VERSION ""

NS_ :

BS_:

BU_: DVT_Cntrl VehDynCntrl
VAL_TABLE_ SpeedLimit_Source 7 "Reverse Limit" 6 "DTS Fault Limit" 5 "Limp Mode Limit" 4 "ADAS Limit" 3 "HMI Limit" 2 "Safety Limit" 1 "Critical Motor Speed Limit" 0 "No Limit" ;
VAL_TABLE_ MapCheckStatus 2 "Parameters incorrect" 1 "Parameters selectively correct" 0 "Parameters correct" ;
VAL_TABLE_ DrRA_BrPedState 3 "Error" 2 "is being pressed" 1 "is not being pressed" 0 "Not avaible" ;
VAL_TABLE_ DVT_DrRA_Prms_Chk_St 2 "DrRA_P_SCor" 1 "DrRA_P_Cor" 0 "DrRA_P_Incor" ;
VAL_TABLE_ DVT_Chosen_Ctrl 1 "Ctrl_fr_AccP" 0 "Ctrl_fr_AI" ;

BO_ 3221225472 VECTOR__INDEPENDENT_SIG_MSG: 0 Vector__XXX
 SG_ ORTL_OTLIM : 0|4@1+ (500,0) [0|7500] "Nm" Vector__XXX
 SG_ ORTL_ORLIM : 0|4@1+ (500,0) [0|7500] "Nm" Vector__XXX
 SG_ ELPC_OvrldCoef : 0|8@1+ (1,0) [0|255] "%" Vector__XXX
 SG_ TrqLimBySpeed : 0|1@1+ (1,0) [0|1] "" Vector__XXX
 SG_ DrRA_P_ChkSt : 0|2@1+ (1,0) [0|0] "" Vector__XXX
 SG_ RotCritMot2Spd : 0|8@1+ (130,0) [0|33150] "RPM" Vector__XXX
 SG_ RotCritMot1Spd : 0|8@1+ (130,0) [0|33150] "RPM" Vector__XXX
 SG_ FreeDebugFlag2 : 0|1@1+ (1,0) [0|0] "" Vector__XXX
 SG_ FreeDebugFlag1 : 0|1@1+ (1,0) [0|0] "" Vector__XXX
 SG_ IsBrPedPushed : 0|1@1+ (1,0) [0|1] "" Vector__XXX
 SG_ IsBreakPedError : 0|1@1+ (1,0) [0|1] "" Vector__XXX
 SG_ PedalErrorProcessing : 0|1@1+ (1,0) [0|0] "" Vector__XXX
 SG_ IntVehSpdLim : 0|8@1+ (1,0) [0|255] "kph" Vector__XXX
 SG_ TTLimSpdLim : 0|1@1+ (1,0) [0|0] "" Vector__XXX
 SG_ SST_TrqOut : 0|16@1+ (1,-32768) [-32768|32767] "Nm" Vector__XXX
 SG_ RSPDL_DTSFault_LimitValid : 0|1@1+ (1,0) [0|1] "" Vector__XXX

BO_ 2381399806 DVT_RSPDL_Debug: 8 Vector__XXX
 SG_ LMP_LimpReqSrc7 : 55|1@1+ (1,0) [0|1] "" Vector__XXX
 SG_ LMP_LimpRequest : 57|1@1+ (1,0) [0|1] "" Vector__XXX
 SG_ RSPDL_Safety_LimitValid : 60|1@1+ (1,0) [0|1] "" Vector__XXX
 SG_ RSPDL_Reverse_LimitValid : 59|1@1+ (1,0) [0|1] "" Vector__XXX
 SG_ RSPDL_LimpMode_LimitValid : 58|1@1+ (1,0) [0|1] "" Vector__XXX
 SG_ RSPDL_Internal_LimitValid : 56|1@1+ (1,0) [0|1] "" Vector__XXX
 SG_ RSPDL_LimpReq : 46|1@1+ (1,0) [0|1] "" Vector__XXX
 SG_ RSPDL_Limp_Limit : 32|8@1+ (1,0) [0|255] "kph" Vector__XXX
 SG_ RSPDL_HMI_LimitValid : 54|1@1+ (1,0) [0|1] "" Vector__XXX
 SG_ RSPDL_ADAS_LimitValid : 53|1@1+ (1,0) [0|1] "" Vector__XXX
 SG_ LMP_LimpReqSrc6 : 52|1@1+ (1,0) [0|1] "" Vector__XXX
 SG_ LMP_LimpReqSrc5 : 51|1@1+ (1,0) [0|1] "" Vector__XXX
 SG_ LMP_LimpReqSrc4 : 50|1@1+ (1,0) [0|1] "" Vector__XXX
 SG_ LMP_LimpReqSrc3 : 49|1@1+ (1,0) [0|1] "" Vector__XXX
 SG_ LMP_LimpReqSrc2 : 48|1@1+ (1,0) [0|1] "" Vector__XXX
 SG_ LMP_LimpReqSrc1 : 47|1@1+ (1,0) [0|1] "" Vector__XXX
 SG_ RSPDL_IsTqLimdBySpdLim : 45|1@1+ (1,0) [0|1] "" Vector__XXX
 SG_ VSLC_IsIntSpdLimAcv : 44|1@1+ (1,0) [0|1] "" Vector__XXX
 SG_ RSPDL_Limit_Source : 40|4@1+ (1,0) [0|15] "" Vector__XXX
 SG_ RSPDL_Internal_Limit : 24|8@1+ (1,0) [0|255] "kph" Vector__XXX
 SG_ RSPDL_HMI_Limit : 16|8@1+ (1,0) [0|255] "kph" Vector__XXX
 SG_ RSPDL_ADAS_Limit : 8|8@1+ (1,0) [0|255] "kph" Vector__XXX
 SG_ RSPDL_Actual_Limit : 0|8@1+ (1,0) [0|255] "kph" Vector__XXX

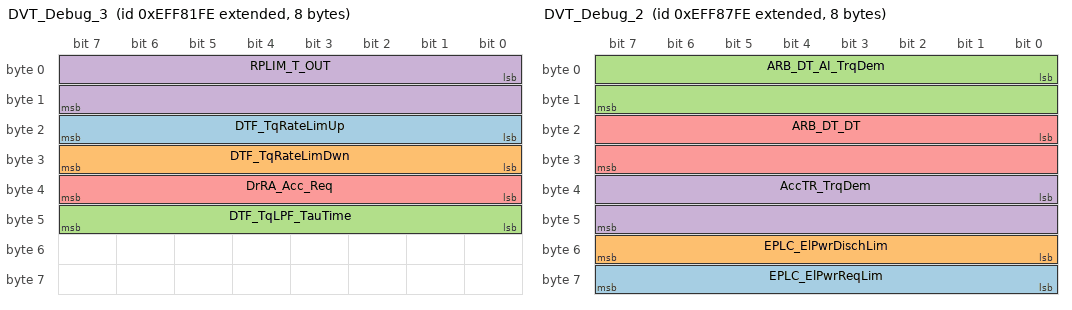
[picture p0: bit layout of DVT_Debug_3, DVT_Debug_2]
BO_ 2399109630 DVT_Debug_3: 8 Vector__XXX
 SG_ DTF_TqRateLimUp : 16|8@1+ (100,0) [0|25500] "Nm/s" Vector__XXX
 SG_ DTF_TqRateLimDwn : 24|8@1+ (100,0) [0|25500] "Nm/s" Vector__XXX
 SG_ DTF_TqLPF_TauTime : 40|8@1+ (0.01,0) [0|2.55] "sec" Vector__XXX
 SG_ RPLIM_T_OUT : 0|16@1+ (1,-32768) [-32768|32767] "Nm" Vector__XXX
 SG_ DrRA_Acc_Req : 32|8@1+ (1,-100) [-100|100] "%" Vector__XXX

BO_ 2399111166 DVT_Debug_2: 8 Vector__XXX
 SG_ EPLC_ElPwrReqLim : 56|8@1+ (10,0) [0|2550] "kW" Vector__XXX
 SG_ EPLC_ElPwrDischLim : 48|8@1+ (10,0) [0|2550] "kW" Vector__XXX
 SG_ ARB_DT_AI_TrqDem : 0|16@1- (1,0) [-32768|32767] "" Vector__XXX
 SG_ AccTR_TrqDem : 32|16@1+ (1,-32768) [-32768|32767] "N*m" Vector__XXX
 SG_ ARB_DT_DT : 16|16@1+ (1,-32768) [-32768|32767] "Nm" Vector__XXX

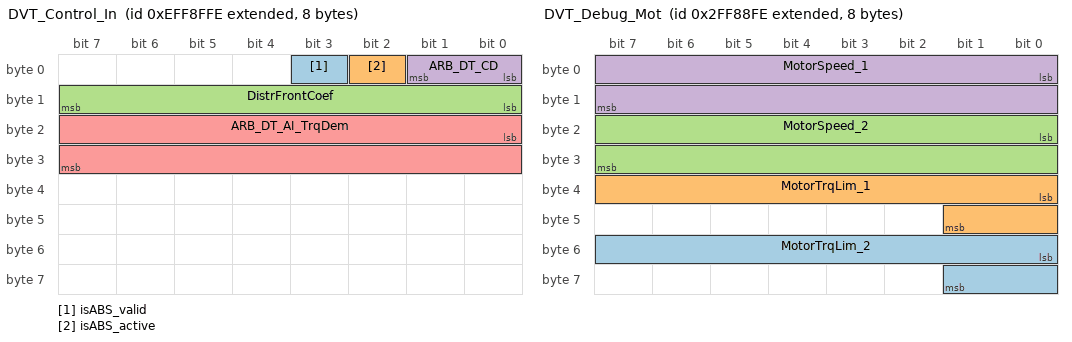
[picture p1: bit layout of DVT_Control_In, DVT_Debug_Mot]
BO_ 2399113214 DVT_Control_In: 8 Vector__XXX
 SG_ isABS_valid : 3|1@1+ (1,0) [0|1] "" Vector__XXX
 SG_ isABS_active : 2|1@1+ (1,0) [0|1] "" Vector__XXX
 SG_ DistrFrontCoef : 8|8@1+ (0.005,0) [0|1.275] "" Vector__XXX
 SG_ ARB_DT_CD : 0|2@1+ (1,0) [0|3] "" Vector__XXX
 SG_ ARB_DT_AI_TrqDem : 16|16@1- (1,0) [-32768|32767] "" Vector__XXX

BO_ 2197784830 DVT_Debug_Mot: 8 Vector__XXX
 SG_ MotorTrqLim_2 : 48|10@1+ (1,0) [0|1023] "" Vector__XXX
 SG_ MotorTrqLim_1 : 32|10@1+ (1,0) [0|1023] "" Vector__XXX
 SG_ MotorSpeed_2 : 16|16@1+ (1,0) [0|65535] "" Vector__XXX
 SG_ MotorSpeed_1 : 0|16@1+ (1,0) [0|65535] "" Vector__XXX

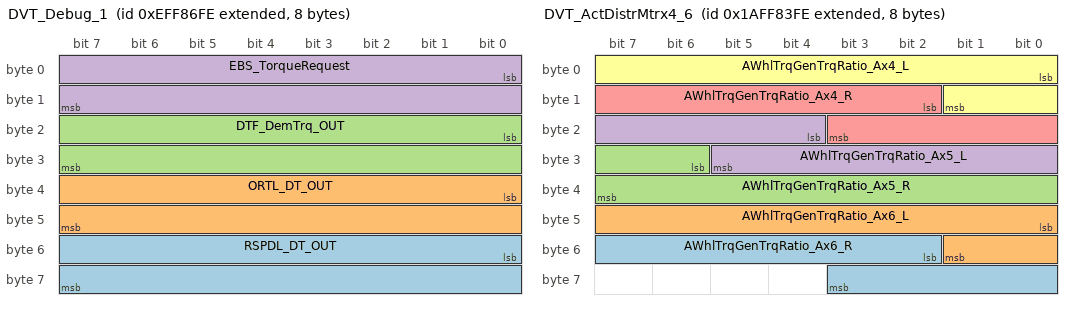
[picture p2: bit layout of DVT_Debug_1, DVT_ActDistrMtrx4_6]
BO_ 2399110910 DVT_Debug_1: 8 Vector__XXX
 SG_ RSPDL_DT_OUT : 48|16@1+ (1,-32768) [-32768|32767] "Nm" Vector__XXX
 SG_ ORTL_DT_OUT : 32|16@1+ (1,-32768) [-32768|32767] "Nm" Vector__XXX
 SG_ DTF_DemTrq_OUT : 16|16@1+ (1,-32768) [-32768|32767] "Nm" Vector__XXX
 SG_ EBS_TorqueRequest : 0|16@1+ (1,-32768) [-32768|32767] "Nm" Vector__XXX

BO_ 2600436734 DVT_ActDistrMtrx4_6: 8 DVT_Cntrl
 SG_ AWhlTrqGenTrqRatio_Ax6_R : 50|10@1+ (0.001,0) [0|1] "" Vector__XXX
 SG_ AWhlTrqGenTrqRatio_Ax6_L : 40|10@1+ (0.001,0) [0|1] "" Vector__XXX
 SG_ AWhlTrqGenTrqRatio_Ax5_R : 30|10@1+ (0.001,0) [0|1] "" Vector__XXX
 SG_ AWhlTrqGenTrqRatio_Ax5_L : 20|10@1+ (0.001,0) [0|1] "" Vector__XXX
 SG_ AWhlTrqGenTrqRatio_Ax4_R : 10|10@1+ (0.001,0) [0|1] "" Vector__XXX
 SG_ AWhlTrqGenTrqRatio_Ax4_L : 0|10@1+ (0.001,0) [0|1] "" Vector__XXX

BO_ 2600438270 DVT_Diagnostics: 8 DVT_Cntrl
 SG_ DTF_TqPreprocIsOn : 38|1@1+ (1,0) [0|0] "" Vector__XXX
 SG_ DrRA_RecChoiceProc : 32|3@1+ (1,0) [0|7] "" Vector__XXX
 SG_ DrRA_MapChoiceFwdProc : 35|3@1+ (1,0) [0|7] "" Vector__XXX
 SG_ DTF_TqLimRateIsOn : 40|1@1+ (1,0) [0|0] "" Vector__XXX
 SG_ DTF_TqLPFIsOn : 41|1@1+ (1,0) [0|0] "" Vector__XXX
 SG_ DTF_DiagWarning : 39|1@1+ (1,0) [0|0] "" Vector__XXX
 SG_ ARB_DT_TrqProhib : 25|1@1+ (1,0) [0|0] "" Vector__XXX
 SG_ ARB_DT_isTTAllow : 31|1@1+ (1,0) [0|0] "" Vector__XXX
 SG_ ARB_DT_isRTAllow : 27|1@1+ (1,0) [0|0] "" Vector__XXX
 SG_ TTDerRPLim : 26|1@1+ (1,0) [0|0] "" Vector__XXX
 SG_ TrqProactLim : 24|1@1+ (1,0) [0|0] "" Vector__XXX
 SG_ pedalProc_dbg : 28|3@1+ (1,0) [0|0] "" Vector__XXX
 SG_ ARB_DT_isABS_valid : 23|1@1+ (1,0) [0|1] "" Vector__XXX
 SG_ ARB_DT_isABS_active : 22|1@1+ (1,0) [0|1] "" Vector__XXX
 SG_ ARB_DT_CD : 20|2@1+ (1,0) [0|3] "" Vector__XXX
 SG_ DrRA_BrPedState : 18|2@1+ (1,0) [0|3] "" Vector__XXX
 SG_ ARB_CD_blocked : 17|1@1+ (1,0) [0|1] "" Vector__XXX
 SG_ ORTL_ITLimFlag : 16|1@1+ (1,0) [0|1] "" Vector__XXX
 SG_ DT_system_warn_st : 11|3@1+ (1,0) [0|7] "" Vector__XXX
 SG_ DT_GearBox_fault_st : 14|2@1+ (1,0) [0|3] "" Vector__XXX
 SG_ MapChckSt : 9|2@1+ (1,0) [0|0] "" Vector__XXX
 SG_ EBS_SrcValFlag : 8|1@1+ (1,0) [0|0] "" Vector__XXX
 SG_ IntSpdValFlag : 7|1@1+ (1,0) [0|0] "" Vector__XXX
 SG_ AccTR_Prms_Incorr : 4|1@1+ (1,0) [0|0] "" Vector__XXX
 SG_ CtrlSrcSelBlckd : 5|1@1+ (1,0) [0|0] "" Vector__XXX
 SG_ AI_SrcValFlag : 3|1@1+ (1,0) [0|0] "" Vector__XXX
 SG_ ChosenCtrlSrc : 0|2@1+ (1,0) [0|0] "" Vector__XXX
 SG_ DefDistribUnavail : 2|1@1+ (1,0) [0|0] "" Vector__XXX
 SG_ DefDistribInUse : 6|1@1+ (1,0) [0|0] "" Vector__XXX

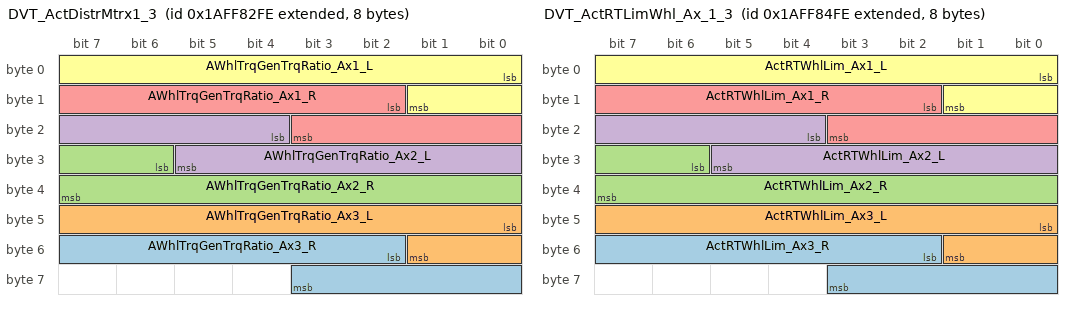
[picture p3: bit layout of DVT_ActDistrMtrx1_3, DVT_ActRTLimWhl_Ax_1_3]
BO_ 2600436478 DVT_ActDistrMtrx1_3: 8 DVT_Cntrl
 SG_ AWhlTrqGenTrqRatio_Ax3_R : 50|10@1+ (0.001,0) [0|1] "" Vector__XXX
 SG_ AWhlTrqGenTrqRatio_Ax3_L : 40|10@1+ (0.001,0) [0|1] "" Vector__XXX
 SG_ AWhlTrqGenTrqRatio_Ax2_R : 30|10@1+ (0.001,0) [0|1] "" Vector__XXX
 SG_ AWhlTrqGenTrqRatio_Ax2_L : 20|10@1+ (0.001,0) [0|1] "" Vector__XXX
 SG_ AWhlTrqGenTrqRatio_Ax1_R : 10|10@1+ (0.001,0) [0|1] "" Vector__XXX
 SG_ AWhlTrqGenTrqRatio_Ax1_L : 0|10@1+ (0.001,0) [0|1] "" Vector__XXX

BO_ 2600436990 DVT_ActRTLimWhl_Ax_1_3: 8 DVT_Cntrl
 SG_ ActRTWhlLim_Ax3_R : 50|10@1+ (8,0) [0|8144] "N*m"  VehDynCntrl
 SG_ ActRTWhlLim_Ax3_L : 40|10@1+ (8,0) [0|8144] "N*m"  VehDynCntrl
 SG_ ActRTWhlLim_Ax2_R : 30|10@1+ (8,0) [0|8144] "N*m"  VehDynCntrl
 SG_ ActRTWhlLim_Ax2_L : 20|10@1+ (8,0) [0|8144] "N*m"  VehDynCntrl
 SG_ ActRTWhlLim_Ax1_R : 10|10@1+ (8,0) [0|8144] "N*m"  VehDynCntrl
 SG_ ActRTWhlLim_Ax1_L : 0|10@1+ (8,0) [0|8144] "N*m"  VehDynCntrl

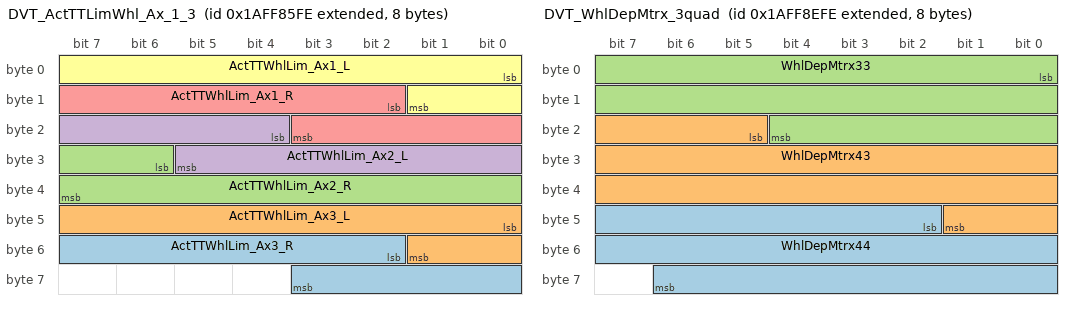
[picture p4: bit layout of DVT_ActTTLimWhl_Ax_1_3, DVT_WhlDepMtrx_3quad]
BO_ 2600437246 DVT_ActTTLimWhl_Ax_1_3: 8 DVT_Cntrl
 SG_ ActTTWhlLim_Ax3_R : 50|10@1+ (8,0) [0|8144] "N*m"  VehDynCntrl
 SG_ ActTTWhlLim_Ax3_L : 40|10@1+ (8,0) [0|8144] "N*m"  VehDynCntrl
 SG_ ActTTWhlLim_Ax2_R : 30|10@1+ (8,0) [0|8144] "N*m"  VehDynCntrl
 SG_ ActTTWhlLim_Ax2_L : 20|10@1+ (8,0) [0|8144] "N*m"  VehDynCntrl
 SG_ ActTTWhlLim_Ax1_R : 10|10@1+ (8,0) [0|8144] "N*m"  VehDynCntrl
 SG_ ActTTWhlLim_Ax1_L : 0|10@1+ (8,0) [0|8144] "N*m"  VehDynCntrl

BO_ 2600439550 DVT_WhlDepMtrx_3quad: 8 DVT_Cntrl
 SG_ WhlDepMtrx44 : 42|21@1+ (1E-005,-10) [-10|10] ""  VehDynCntrl
 SG_ WhlDepMtrx43 : 21|21@1+ (1E-005,-10) [-10|10] ""  VehDynCntrl
 SG_ WhlDepMtrx33 : 0|21@1+ (1E-005,-10) [-10|10] ""  VehDynCntrl

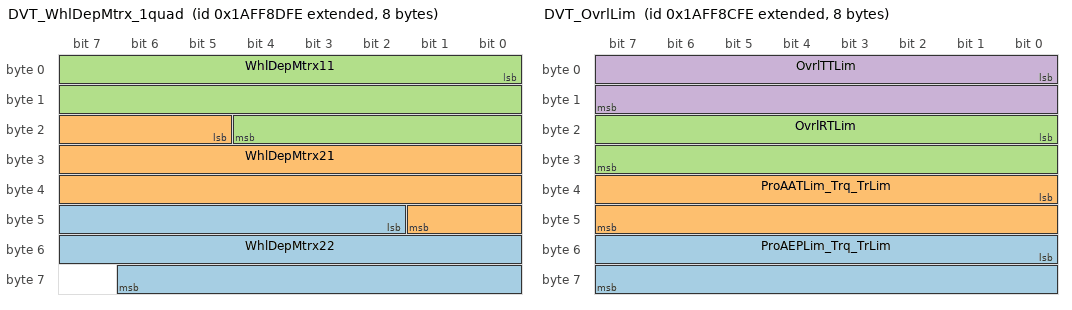
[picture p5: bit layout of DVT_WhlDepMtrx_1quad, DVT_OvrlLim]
BO_ 2600439294 DVT_WhlDepMtrx_1quad: 8 DVT_Cntrl
 SG_ WhlDepMtrx22 : 42|21@1+ (1E-005,-10) [-10|10] ""  VehDynCntrl
 SG_ WhlDepMtrx21 : 21|21@1+ (1E-005,-10) [-10|10] ""  VehDynCntrl
 SG_ WhlDepMtrx11 : 0|21@1+ (1E-005,-10) [-10|10] ""  VehDynCntrl

BO_ 2600439038 DVT_OvrlLim: 8 DVT_Cntrl
 SG_ ProAEPLim_Trq_TrLim : 48|16@1+ (1,0) [0|65535] "" Vector__XXX
 SG_ ProAATLim_Trq_TrLim : 32|16@1+ (1,0) [0|65535] "" Vector__XXX
 SG_ OvrlRTLim : 16|16@1+ (1.5,0) [0|96382] "N*m" Vector__XXX
 SG_ OvrlTTLim : 0|16@1+ (1.5,0) [0|96382] "N*m" Vector__XXX

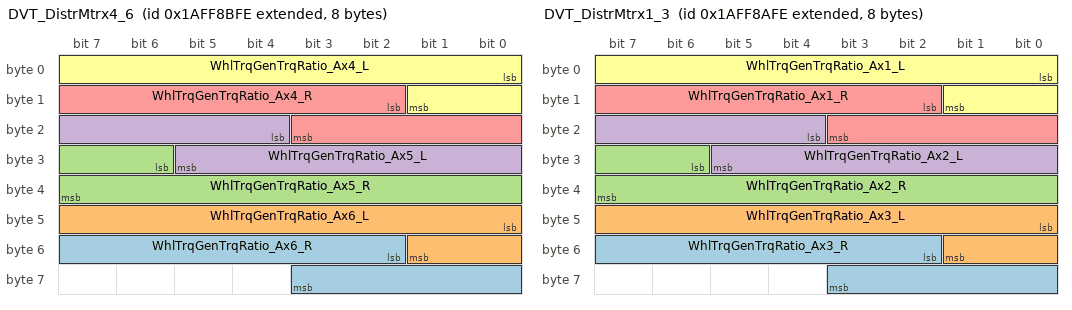
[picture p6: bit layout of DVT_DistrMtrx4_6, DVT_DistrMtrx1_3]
BO_ 2600438782 DVT_DistrMtrx4_6: 8 VehDynCntrl
 SG_ WhlTrqGenTrqRatio_Ax6_R : 50|10@1+ (0.001,0) [0|1] ""  DVT_Cntrl
 SG_ WhlTrqGenTrqRatio_Ax6_L : 40|10@1+ (0.001,0) [0|1] ""  DVT_Cntrl
 SG_ WhlTrqGenTrqRatio_Ax5_R : 30|10@1+ (0.001,0) [0|1] ""  DVT_Cntrl
 SG_ WhlTrqGenTrqRatio_Ax5_L : 20|10@1+ (0.001,0) [0|1] ""  DVT_Cntrl
 SG_ WhlTrqGenTrqRatio_Ax4_R : 10|10@1+ (0.001,0) [0|1] ""  DVT_Cntrl
 SG_ WhlTrqGenTrqRatio_Ax4_L : 0|10@1+ (0.001,0) [0|1] ""  DVT_Cntrl

BO_ 2600438526 DVT_DistrMtrx1_3: 8 VehDynCntrl
 SG_ WhlTrqGenTrqRatio_Ax3_R : 50|10@1+ (0.001,0) [0|1] ""  DVT_Cntrl
 SG_ WhlTrqGenTrqRatio_Ax3_L : 40|10@1+ (0.001,0) [0|1] ""  DVT_Cntrl
 SG_ WhlTrqGenTrqRatio_Ax2_R : 30|10@1+ (0.001,0) [0|1] ""  DVT_Cntrl
 SG_ WhlTrqGenTrqRatio_Ax2_L : 20|10@1+ (0.001,0) [0|1] ""  DVT_Cntrl
 SG_ WhlTrqGenTrqRatio_Ax1_R : 10|10@1+ (0.001,0) [0|1] ""  DVT_Cntrl
 SG_ WhlTrqGenTrqRatio_Ax1_L : 0|10@1+ (0.001,0) [0|1] ""  DVT_Cntrl

CM_ BO_ 3221225472 "This is a message for not used signals, created by Vector CANdb++ DBC OLE DB Provider.";
CM_ SG_ 3221225472 ORTL_OTLIM "Overall reference torque limitator";
CM_ SG_ 3221225472 ORTL_ORLIM "Overall reference torque limitator";
CM_ SG_ 3221225472 ELPC_OvrldCoef "Electric power limit calculation: Overload coefficient";
CM_ SG_ 3221225472 DrRA_P_ChkSt "State of the check of the parameters with DrRA prefix (DrRA_P_Incor - all parameters is incorrect,  DrRA_P_Cor - all parameters is correct)";
CM_ SG_ 3221225472 RotCritMot2Spd "Rotational Critical Motor 2 Speed";
CM_ SG_ 3221225472 RotCritMot1Spd "Rotational Critical Motor 1 Speed";
CM_ SG_ 3221225472 FreeDebugFlag2 "Any debug flag";
CM_ SG_ 3221225472 FreeDebugFlag1 "Any debug signal";
CM_ SG_ 3221225472 PedalErrorProcessing "DTS.COMP.PP-022 v1547
If true, there are one of this issue:
1. Brake pedal state error
2. Acceleration pedal error
3. Pedal position threshold high < low";
CM_ SG_ 3221225472 IntVehSpdLim "The vehicle speed limit that was set by an internal limitation";
CM_ SG_ 3221225472 TTLimSpdLim "Traction torque is limited by speed limitation, flag";
CM_ SG_ 3221225472 SST_TrqOut "Smooth Start torque";
CM_ SG_ 2381399806 LMP_LimpReqSrc7 "Limp mode torque limit source 1: Ramp";
CM_ SG_ 2381399806 LMP_LimpReqSrc6 "Limp mode torque limit source 1: Ramp";
CM_ SG_ 2381399806 LMP_LimpReqSrc5 "Limp mode torque limit source 5: DOOR
";
CM_ SG_ 2381399806 LMP_LimpReqSrc4 "Limp mode torque limit source 4: SUSP";
CM_ SG_ 2381399806 LMP_LimpReqSrc3 "Limp mode torque limit source 1: STEERING
";
CM_ SG_ 2381399806 LMP_LimpReqSrc2 "Limp mode torque limit source 1: BRAKE
";
CM_ SG_ 2381399806 LMP_LimpReqSrc1 "Limp mode torque limit source 1: HV";
CM_ SG_ 2381399806 RSPDL_IsTqLimdBySpdLim "RSPDL_ITLSL: IsTorqueLimitedBySpeedLimit Torque Reactive speed limitaion - speed limit achieved, Traction torque is limited by speed limitation";
CM_ SG_ 2381399806 VSLC_IsIntSpdLimAcv "IsInternalSpeedLimitActive: True mean that an internal vehicle speed limitation is set.";
CM_ SG_ 2399109630 DTF_TqRateLimUp "DTF Torque Rate limit up";
CM_ SG_ 2399109630 DTF_TqRateLimDwn "DTF Torque rate limit down";
CM_ SG_ 2399109630 DTF_TqLPF_TauTime "DTF LPF Tau Timeconst sec";
CM_ SG_ 2399109630 RPLIM_T_OUT "Reactive Power limitaion torque filter";
CM_ SG_ 2399109630 DrRA_Acc_Req "Driver request analysis: acceleration request";
CM_ SG_ 2399111166 EPLC_ElPwrReqLim "Electric power limit calculation";
CM_ SG_ 2399111166 EPLC_ElPwrDischLim "Electric power limit calculation";
CM_ SG_ 2399111166 AccTR_TrqDem "Acceleration torque regulator: TorqueDemandDriver";
CM_ SG_ 2399111166 ARB_DT_DT "Arbitrator of Demanded torque";
CM_ SG_ 2399113214 DistrFrontCoef "Define distribution for Front Axle. Rear axle distribution is 1- Front Axle";
CM_ SG_ 2399113214 ARB_DT_CD "Signal for requesting torque control source.";
CM_ SG_ 2399110910 RSPDL_DT_OUT "Reactive speed limitaion torque filter

";
CM_ SG_ 2399110910 ORTL_DT_OUT "Overall reference torque limitator";
CM_ SG_ 2399110910 DTF_DemTrq_OUT "Demanded torque filter";
CM_ SG_ 2399110910 EBS_TorqueRequest "Signal from EBS - Torque request";
CM_ BO_ 2600436734 "Distribution matrix part for axles from 4th to 6th ";
CM_ SG_ 2600436734 AWhlTrqGenTrqRatio_Ax6_R "Wheel torque to general torque ratio for right wheel on axle 6";
CM_ SG_ 2600436734 AWhlTrqGenTrqRatio_Ax6_L "Wheel torque to general torque ratio for left wheel on axle 6";
CM_ SG_ 2600436734 AWhlTrqGenTrqRatio_Ax5_R "Wheel torque to general torque ratio for right wheel on axle 5";
CM_ SG_ 2600436734 AWhlTrqGenTrqRatio_Ax5_L "Wheel torque to general torque ratio for left wheel on axle 5";
CM_ SG_ 2600436734 AWhlTrqGenTrqRatio_Ax4_R "Wheel torque to general torque ratio for right wheel on axle 4";
CM_ SG_ 2600436734 AWhlTrqGenTrqRatio_Ax4_L "Wheel torque to general torque ratio for left wheel on axle 4";
CM_ BO_ 2600438270 "Diagnostics message";
CM_ SG_ 2600438270 DTF_TqPreprocIsOn "DTF TorquePreprocessing is On";
CM_ SG_ 2600438270 DTF_TqLimRateIsOn "DTF Rate limiter Is On";
CM_ SG_ 2600438270 DTF_TqLPFIsOn "DTF Low pass filter LPF Is On";
CM_ SG_ 2600438270 DTF_DiagWarning "DTF Diagnostics Warning is active";
CM_ SG_ 2600438270 ARB_DT_TrqProhib "IsTorqueProhibited";
CM_ SG_ 2600438270 ARB_DT_isTTAllow "IsTractionTorqueAllowed";
CM_ SG_ 2600438270 ARB_DT_isRTAllow "IsRegenerationTorqueAllowed";
CM_ SG_ 2600438270 TTDerRPLim "Traction torque is derated by reactive power limitation";
CM_ SG_ 2600438270 TrqProactLim "Overall torque was proactively limited, flag";
CM_ SG_ 2600438270 ARB_DT_CD "Signal for requesting torque control source.";
CM_ SG_ 2600438270 ARB_CD_blocked "Control Demand block";
CM_ SG_ 2600438270 ORTL_ITLimFlag "Is torque proactive limited";
CM_ SG_ 2600438270 DT_system_warn_st "Arbitrator of Demanded torque";
CM_ SG_ 2600438270 DT_GearBox_fault_st "Arbitrator of Demanded torque";
CM_ SG_ 2600438270 MapChckSt "Calibration tables for pedal mapping check status";
CM_ SG_ 2600438270 EBS_SrcValFlag "EBS source is valid flag";
CM_ SG_ 2600438270 IntSpdValFlag "Internal speed validity flag";
CM_ SG_ 2600438270 AccTR_Prms_Incorr "1 - Parameters with AccTR prefix is invalid";
CM_ SG_ 2600438270 CtrlSrcSelBlckd "1 - Selection of control source is blocked, flag";
CM_ SG_ 2600438270 AI_SrcValFlag "Demand from AI is valid";
CM_ SG_ 2600438270 ChosenCtrlSrc "Chosen control source";
CM_ SG_ 2600438270 DefDistribUnavail "Diagnostic flag indicating that default distribution is not possible to set (1- default distribution is not possible to set)";
CM_ SG_ 2600438270 DefDistribInUse "Diagnostic flag about using default distribution (1- default distribution is using)";
CM_ BO_ 2600436478 "Actual distribution matrix part for axles from 1st to 3rd ";
CM_ SG_ 2600436478 AWhlTrqGenTrqRatio_Ax3_R "Wheel torque to general torque ratio for right wheel on axle 2";
CM_ SG_ 2600436478 AWhlTrqGenTrqRatio_Ax3_L "Wheel torque to general torque ratio for left wheel on axle 3";
CM_ SG_ 2600436478 AWhlTrqGenTrqRatio_Ax2_R "Wheel torque to general torque ratio for right wheel on axle 2";
CM_ SG_ 2600436478 AWhlTrqGenTrqRatio_Ax2_L "Wheel torque to general torque ratio for left wheel on axle 2";
CM_ SG_ 2600436478 AWhlTrqGenTrqRatio_Ax1_R "Wheel torque to general torque ratio for right wheel on axle 1";
CM_ SG_ 2600436478 AWhlTrqGenTrqRatio_Ax1_L "Wheel torque to general torque ratio for left wheel on axle 1";
CM_ BO_ 2600436990 "A matrix of actual recuperation torque limitation of each wheel for 1 - 3 axle";
CM_ SG_ 2600436990 ActRTWhlLim_Ax3_R "Maximum recuperation torque for right wheel on axle 3.";
CM_ SG_ 2600436990 ActRTWhlLim_Ax3_L "Maximum recuperation torque for left wheel on axle 3.";
CM_ SG_ 2600436990 ActRTWhlLim_Ax2_R "Maximum recuperation torque for right wheel on axle 2.";
CM_ SG_ 2600436990 ActRTWhlLim_Ax2_L "Maximum recuperation torque for left wheel on axle 2.";
CM_ SG_ 2600436990 ActRTWhlLim_Ax1_R "Maximum recuperation torque for right wheel on axle 1.";
CM_ SG_ 2600436990 ActRTWhlLim_Ax1_L "Maximum recuperation torque for left wheel on axle 1.";
CM_ BO_ 2600437246 "A matrix of actual traction torque limitation of each wheel for 1 - 3 axle";
CM_ SG_ 2600437246 ActTTWhlLim_Ax3_R "Maximum traction torque for right wheel on axle 3.";
CM_ SG_ 2600437246 ActTTWhlLim_Ax3_L "Maximum traction torque for left wheel on axle 3.";
CM_ SG_ 2600437246 ActTTWhlLim_Ax2_R "Maximum traction torque for right wheel on axle 2.";
CM_ SG_ 2600437246 ActTTWhlLim_Ax2_L "Maximum traction torque for left wheel on axle 2.";
CM_ SG_ 2600437246 ActTTWhlLim_Ax1_R "Maximum traction torque for right wheel on axle 1.";
CM_ SG_ 2600437246 ActTTWhlLim_Ax1_L "Maximum traction torque for left wheel on axle 1.";
CM_ BO_ 2600439550 "1-st quadrant of 2 axles vehicle wheel dependent matrix.";
CM_ SG_ 2600439550 WhlDepMtrx44 "Element on row 4 column 4 of wheel dependent matrix";
CM_ SG_ 2600439550 WhlDepMtrx43 "Element on row 4 column 3 of wheel dependent matrix";
CM_ SG_ 2600439550 WhlDepMtrx33 "Element on row 3 column 3 of wheel dependent matrix";
CM_ BO_ 2600439294 "1-st quadrant of 2 axles vehicle wheel dependent matrix.";
CM_ SG_ 2600439294 WhlDepMtrx22 "Element on row 2 column 2 of wheel dependent matrix";
CM_ SG_ 2600439294 WhlDepMtrx21 "Element on row 2 column 1 of wheel dependent matrix";
CM_ SG_ 2600439294 WhlDepMtrx11 "Element on row 1 column 1 of wheel dependent matrix";
CM_ BO_ 2600439038 "Overall limits message with information about limitation acting.";
CM_ SG_ 2600439038 OvrlRTLim "Overall recuperation torque limit";
CM_ SG_ 2600439038 OvrlTTLim "Overall traction torque limit";
CM_ BO_ 2600438782 "Distribution matrix part for axles from 4th to 6th ";
CM_ SG_ 2600438782 WhlTrqGenTrqRatio_Ax6_R "Wheel torque to general torque ratio for right wheel on axle 6";
CM_ SG_ 2600438782 WhlTrqGenTrqRatio_Ax6_L "Wheel torque to general torque ratio for left wheel on axle 6";
CM_ SG_ 2600438782 WhlTrqGenTrqRatio_Ax5_R "Wheel torque to general torque ratio for right wheel on axle 5";
CM_ SG_ 2600438782 WhlTrqGenTrqRatio_Ax5_L "Wheel torque to general torque ratio for left wheel on axle 5";
CM_ SG_ 2600438782 WhlTrqGenTrqRatio_Ax4_R "Wheel torque to general torque ratio for right wheel on axle 4";
CM_ SG_ 2600438782 WhlTrqGenTrqRatio_Ax4_L "Wheel torque to general torque ratio for left wheel on axle 4";
CM_ BO_ 2600438526 "Distribution matrix part for axles from 1st to 3rd ";
CM_ SG_ 2600438526 WhlTrqGenTrqRatio_Ax3_R "Wheel torque to general torque ratio for right wheel on axle 2";
CM_ SG_ 2600438526 WhlTrqGenTrqRatio_Ax3_L "Wheel torque to general torque ratio for left wheel on axle 3";
CM_ SG_ 2600438526 WhlTrqGenTrqRatio_Ax2_R "Wheel torque to general torque ratio for right wheel on axle 2";
CM_ SG_ 2600438526 WhlTrqGenTrqRatio_Ax2_L "Wheel torque to general torque ratio for left wheel on axle 2";
CM_ SG_ 2600438526 WhlTrqGenTrqRatio_Ax1_R "Wheel torque to general torque ratio for right wheel on axle 1";
CM_ SG_ 2600438526 WhlTrqGenTrqRatio_Ax1_L "Wheel torque to general torque ratio for left wheel on axle 1";
BA_DEF_ BO_  "SendOnChange" ENUM  "No","Yes";
BA_DEF_ SG_  "SigType" ENUM  "Default","Range","RangeSigned","ASCII","Discrete","Control","ReferencePGN","DTC","StringDelimiter","StringLength","StringLengthControl","MessageCounter","MessageChecksum";
BA_DEF_ SG_  "GenSigEVName" STRING ;
BA_DEF_ SG_  "GenSigILSupport" ENUM  "No","Yes";
BA_DEF_ SG_  "GenSigSendType" ENUM  "Cyclic","OnWrite","OnWriteWithRepetition","OnChange","OnChangeWithRepetition","IfActive","IfActiveWithRepetition","NoSigSendType";
BA_DEF_ SG_  "GenSigStartValue" INT 0 2147483647;
BA_DEF_ BO_  "GenMsgDelayTime" INT 0 1000;
BA_DEF_ BO_  "GenMsgILSupport" ENUM  "No","Yes";
BA_DEF_ BO_  "Producer" STRING ;
BA_DEF_ BU_  "NmStationAddress" INT 0 255;
BA_DEF_ BO_  "GenMsgSendType" ENUM  "cyclic","NotUsed","IfActive","NotUsed","NotUsed","NotUsed","NotUsed","NotUsed","noMsgSendType";
BA_DEF_ BO_  "GenMsgRequestable" INT 0 1;
BA_DEF_ BO_  "GenMsgCycleTime" INT 0 3600000;
BA_DEF_  "DBName" STRING ;
BA_DEF_  "BusType" STRING ;
BA_DEF_  "ProtocolType" STRING ;
BA_DEF_ BO_  "VFrameFormat" ENUM  "StandardCAN","ExtendedCAN","reserved","J1939PG";
BA_DEF_DEF_  "SendOnChange" "No";
BA_DEF_DEF_ "Producer" "DTS" ;
BA_DEF_DEF_  "SigType" "Default";
BA_DEF_DEF_  "GenSigEVName" "Env@Nodename_@Signame";
BA_DEF_DEF_  "GenSigILSupport" "Yes";
BA_DEF_DEF_  "GenSigSendType" "NoSigSendType";
BA_DEF_DEF_  "GenSigStartValue" 0;
BA_DEF_DEF_  "GenMsgDelayTime" 0;
BA_DEF_DEF_  "GenMsgILSupport" "Yes";
BA_DEF_DEF_  "NmStationAddress" 254;
BA_DEF_DEF_  "GenMsgSendType" "noMsgSendType";
BA_DEF_DEF_  "GenMsgRequestable" 1;
BA_DEF_DEF_  "GenMsgCycleTime" 0;
BA_DEF_DEF_  "DBName" "";
BA_DEF_DEF_  "BusType" "CAN";
BA_DEF_DEF_  "ProtocolType" "J1939";
BA_DEF_DEF_  "VFrameFormat" "J1939PG";
BA_ "DBName" "DVT";
BA_ "NmStationAddress" BU_ DVT_Cntrl 1;
BA_ "GenMsgCycleTime" BO_ 2381399806 1000;
BA_ "GenMsgDelayTime" BO_ 2381399806 100;
BA_ "SendOnChange" BO_ 2381399806 1;
BA_ "GenMsgCycleTime" BO_ 2399109630 100;
BA_ "GenMsgCycleTime" BO_ 2399111166 100;
BA_ "GenMsgCycleTime" BO_ 2399113214 20;
BA_ "GenMsgCycleTime" BO_ 2197784830 100;
BA_ "GenMsgDelayTime" BO_ 2399110910 10;
BA_ "SendOnChange" BO_ 2399110910 1;
BA_ "GenMsgCycleTime" BO_ 2399110910 1000;
BA_ "GenMsgCycleTime" BO_ 2600436734 10;
BA_ "GenMsgCycleTime" BO_ 2600438270 1000;
BA_ "SendOnChange" BO_ 2600438270 1;
BA_ "GenMsgDelayTime" BO_ 2600438270 100;
BA_ "GenMsgCycleTime" BO_ 2600436478 10;
BA_ "GenMsgCycleTime" BO_ 2600436990 50;
BA_ "GenMsgCycleTime" BO_ 2600437246 50;
BA_ "GenMsgCycleTime" BO_ 2600439550 100;
BA_ "GenMsgCycleTime" BO_ 2600439294 100;
BA_ "GenMsgCycleTime" BO_ 2600439038 100;
BA_ "GenMsgCycleTime" BO_ 2600438782 10;
BA_ "GenMsgCycleTime" BO_ 2600438526 10;
BA_ "GenSigStartValue" SG_ 2399109630 DrRA_Acc_Req 100;
BA_ "GenSigStartValue" SG_ 2399110910 EBS_TorqueRequest 32768;
VAL_ 2381399806 RSPDL_Limit_Source 7 "Reverse Limit" 6 "Limp Mode Limit" 5 "ADAS Limit" 4 "HMI Limit" 3 "Safety Limit" 2 "Critical Motor Speed Limit" 1 "Overrided by the parameter" 0 "No Limit" ;
VAL_ 2600438270 DT_system_warn_st 0 "NoFault" 1 "MinorFault" 2 "MajorFault" 3 "CriticalFault" 4 "CriticalLatched" 7 "NotAvailable" ;
VAL_ 2600438270 DT_GearBox_fault_st 0 "NoFault" 1 "MinorFault" 2 "CriticalFault" 3 "NoAvailable" ;
